# N32A032 register map
Vendor: Nationstech Ltd.; File version: 1.0
Registers are 32-bit, read-write, reset 0x0 unless marked. A register's access mark holds for its fields unless they carry their own. Offsets are from the block's base; [hi:lo] are bit positions; {n}, {i} and the like mark numbered series; 'fields as' and 'values as' point back to an identical list.

## BEEPER1 — Beeper unit
Base 0x40000000
Same registers: BEEPER2 0x40001400
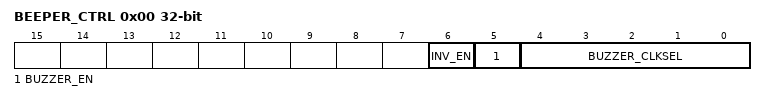
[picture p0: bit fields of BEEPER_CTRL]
0x00 BEEPER_CTRL
  [6] INV_EN, [5] BUZZER_EN, [4:0] BUZZER_CLKSEL

## CAN — Controller area network
Base 0x40006400
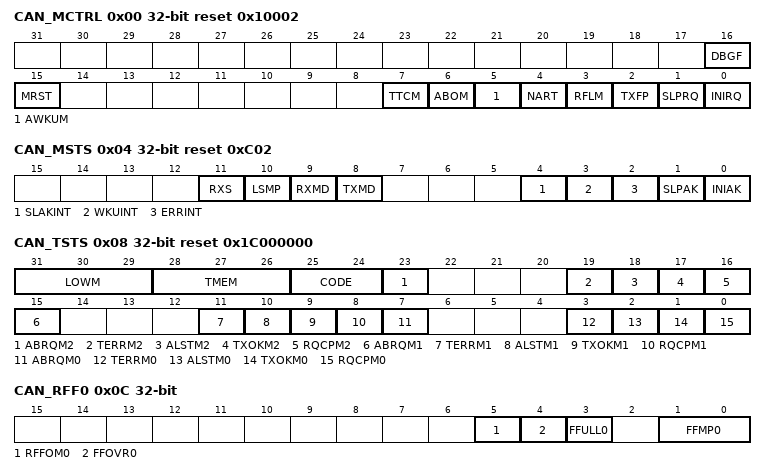
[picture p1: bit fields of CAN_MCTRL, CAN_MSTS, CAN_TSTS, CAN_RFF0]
0x00 CAN_MCTRL reset 0x10002
  [16] DBGF, [15] MRST, [7] TTCM, [6] ABOM, [5] AWKUM, [4] NART, [3] RFLM, [2] TXFP, [1] SLPRQ, [0] INIRQ
0x04 CAN_MSTS reset 0xC02
  [11] RXS, [10] LSMP, [9] RXMD, [8] TXMD, [4] SLAKINT, [3] WKUINT, [2] ERRINT, [1] SLPAK, [0] INIAK
0x08 CAN_TSTS reset 0x1C000000
  [31:29] LOWM, [28:26] TMEM, [25:24] CODE, [23] ABRQM2, [19] TERRM2, [18] ALSTM2, [17] TXOKM2, [16] RQCPM2, [15] ABRQM1, [11] TERRM1, [10] ALSTM1, [9] TXOKM1, [8] RQCPM1, [7] ABRQM0, [3] TERRM0, [2] ALSTM0, [1] TXOKM0, [0] RQCPM0
0x0C CAN_RFF0
  [5] RFFOM0, [4] FFOVR0, [3] FFULL0, [1:0] FFMP0
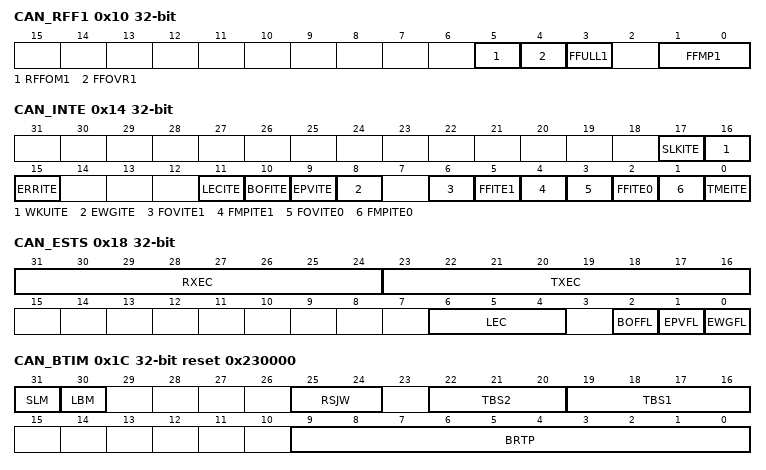
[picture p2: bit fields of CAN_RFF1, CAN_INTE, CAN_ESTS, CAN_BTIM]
0x10 CAN_RFF1
  [5] RFFOM1, [4] FFOVR1, [3] FFULL1, [1:0] FFMP1
0x14 CAN_INTE
  [17] SLKITE, [16] WKUITE, [15] ERRITE, [11] LECITE, [10] BOFITE, [9] EPVITE, [8] EWGITE, [6] FOVITE1, [5] FFITE1, [4] FMPITE1, [3] FOVITE0, [2] FFITE0, [1] FMPITE0, [0] TMEITE
0x18 CAN_ESTS
  [31:24] RXEC, [23:16] TXEC, [6:4] LEC, [2] BOFFL, [1] EPVFL, [0] EWGFL
0x1C CAN_BTIM reset 0x230000
  [31] SLM, [30] LBM, [25:24] RSJW, [22:20] TBS2, [19:16] TBS1, [9:0] BRTP
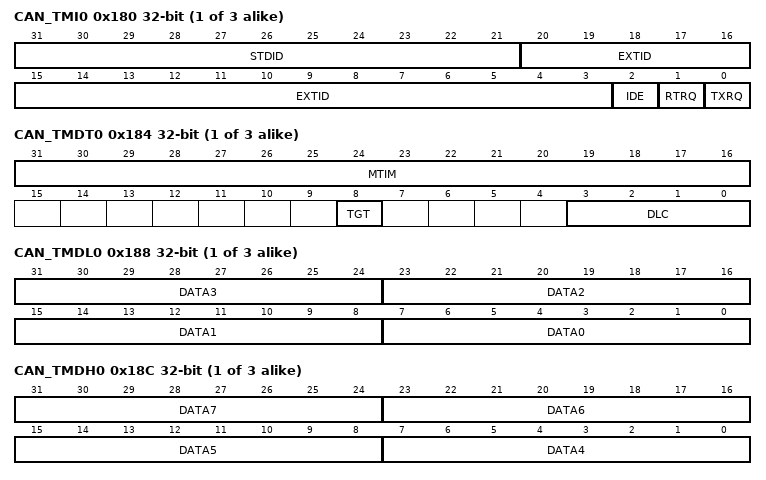
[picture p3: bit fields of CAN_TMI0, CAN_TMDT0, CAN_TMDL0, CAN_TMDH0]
{0x180+0x10*i} CAN_TMI{i} (i=0..2)
  [31:21] STDID, [20:3] EXTID, [2] IDE, [1] RTRQ, [0] TXRQ
{0x184+0x10*i} CAN_TMDT{i} (i=0..2)
  [31:16] MTIM, [8] TGT, [3:0] DLC
{0x188+0x10*i} CAN_TMDL{i} (i=0..2)
  [8n+7:8n] DATA{n} (n=0..3)
{0x18C+0x10*i} CAN_TMDH{i} (i=0..2)
  [8n-25:8n-32] DATA{n} (n=4..7)
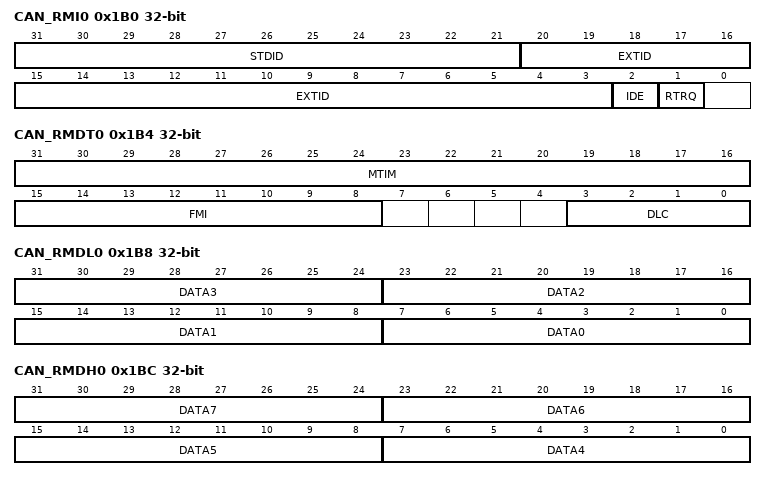
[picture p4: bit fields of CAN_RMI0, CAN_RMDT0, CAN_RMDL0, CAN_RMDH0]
0x1B0 CAN_RMI0
  [31:21] STDID, [20:3] EXTID, [2] IDE, [1] RTRQ
0x1B4 CAN_RMDT0
  [31:16] MTIM, [15:8] FMI, [3:0] DLC
0x1B8 CAN_RMDL0
  [8n+7:8n] DATA{n} (n=0..3)
0x1BC CAN_RMDH0
  [8n-25:8n-32] DATA{n} (n=4..7)
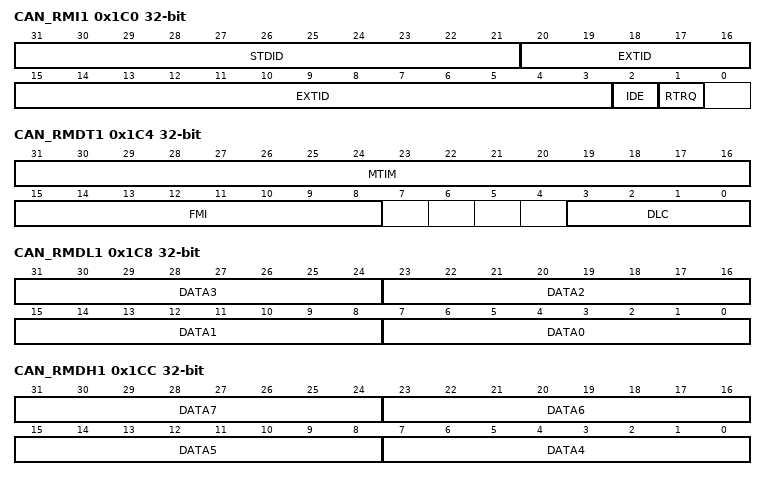
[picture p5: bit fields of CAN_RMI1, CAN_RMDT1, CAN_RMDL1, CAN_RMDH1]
0x1C0 CAN_RMI1
  [31:21] STDID, [20:3] EXTID, [2] IDE, [1] RTRQ
0x1C4 CAN_RMDT1
  [31:16] MTIM, [15:8] FMI, [3:0] DLC
0x1C8 CAN_RMDL1
  [8n+7:8n] DATA{n} (n=0..3)
0x1CC CAN_RMDH1
  [8n-25:8n-32] DATA{n} (n=4..7)
0x200 CAN_FMC reset 0x1
  [0] FINITM
0x204 CAN_FM1
  [13:0] FB
0x20C CAN_FS1
  [13:0] FSC
0x214 CAN_FFA1
  [13:0] FAF
0x21C CAN_FA1
  [13:0] FAC
{0x240+8i} CAN_F{i}B1 (i=0..13)
  [31:0] FBC
{0x244+8i} CAN_F{i}B2 (i=0..13)
  [31:0] FBC

## COMP — comparator
Base 0x40002400
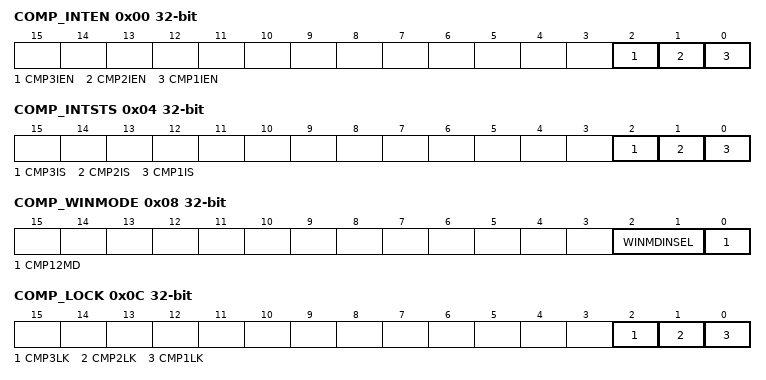
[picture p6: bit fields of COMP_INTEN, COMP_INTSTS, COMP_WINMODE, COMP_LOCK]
0x00 COMP_INTEN
  [2] CMP3IEN, [1] CMP2IEN, [0] CMP1IEN
0x04 COMP_INTSTS
  [2] CMP3IS, [1] CMP2IS, [0] CMP1IS
0x08 COMP_WINMODE
  [2:1] WINMDINSEL, [0] CMP12MD
0x0C COMP_LOCK
  [2] CMP3LK, [1] CMP2LK, [0] CMP1LK
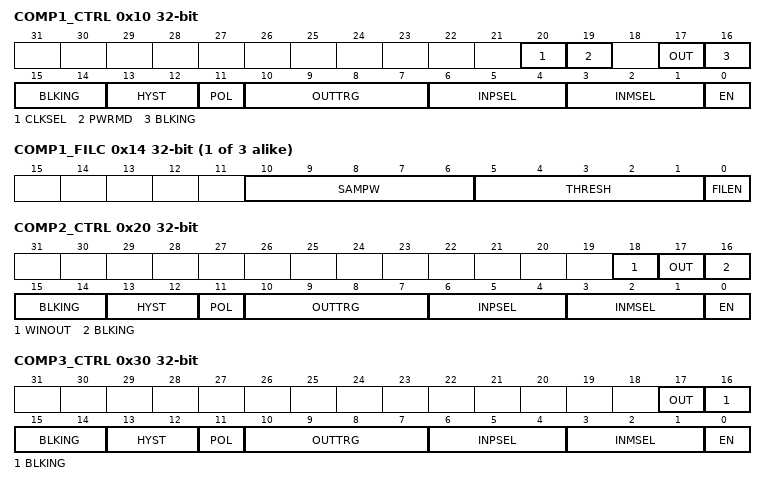
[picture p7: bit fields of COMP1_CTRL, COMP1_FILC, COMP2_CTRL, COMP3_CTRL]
0x10 COMP1_CTRL
  [20] CLKSEL
  [19] PWRMD
  [17] OUT
  [16:14] BLKING
  [13:12] HYST
  [11] POL
  [10:7] OUTTRG — OUTSEL
  [6:4] INPSEL
  [3:1] INMSEL
  [0] EN
{0x4+0x10*i} COMP{i}_FILC (i=1..3)
  [10:6] SAMPW, [5:1] THRESH, [0] FILEN
{0x8+0x10*i} COMP{i}_FILP (i=1..3)
  [15:0] CLKPSC
0x20 COMP2_CTRL
  [18] WINOUT
  [17] OUT
  [16:14] BLKING
  [13:12] HYST
  [11] POL
  [10:7] OUTTRG — OUTSEL
  [6:4] INPSEL
  [3:1] INMSEL
  [0] EN
0x30 COMP3_CTRL
  [17] OUT
  [16:14] BLKING
  [13:12] HYST
  [11] POL
  [10:7] OUTTRG — OUTSEL
  [6:4] INPSEL
  [3:1] INMSEL
  [0] EN
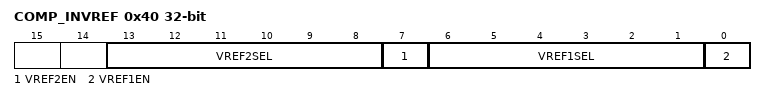
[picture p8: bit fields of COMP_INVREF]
0x40 COMP_INVREF (reset mask 0xFFF)
  [13:8] VREF2SEL, [7] VREF2EN, [6:1] VREF1SEL, [0] VREF1EN

## CRC — cyclic redundancy check
Base 0x40023000
0x00 CRC32DAT reset 0xFFFFFFFF
0x04 CRC32IDAT
  [7:0] CRC32IDAT
0x08 CRC32CTRL
  [0] RESET
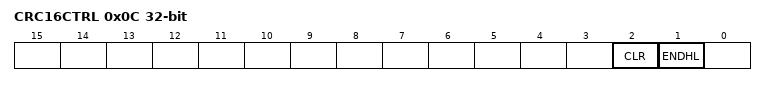
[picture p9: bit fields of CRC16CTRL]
0x0C CRC16CTRL
  [2] CLR, [1] ENDHL
0x10 CRC16DAT
  [7:0] CRC16DAT
0x14 CRC16D
  [15:0] CRC16D
0x18 LRC
  [7:0] LRCDAT

## DMA — Direct memory access controller
Base 0x40020000
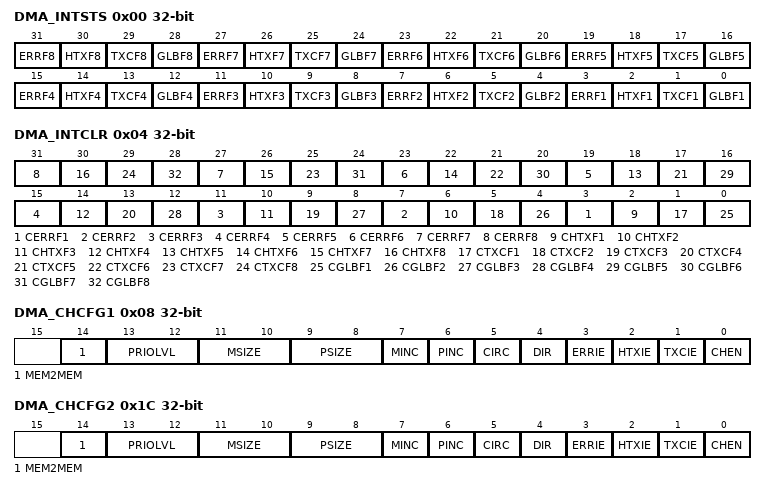
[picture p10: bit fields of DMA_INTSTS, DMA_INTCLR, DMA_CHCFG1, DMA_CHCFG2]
0x00 DMA_INTSTS
  [4n-1] ERRF{n} (n=1..8), [4n-2] HTXF{n} (n=1..8), [4n-3] TXCF{n} (n=1..8), [4n-4] GLBF{n} (n=1..8)
0x04 DMA_INTCLR
  [4n-1] CERRF{n} (n=1..8), [4n-2] CHTXF{n} (n=1..8), [4n-3] CTXCF{n} (n=1..8), [4n-4] CGLBF{n} (n=1..8)
0x08 DMA_CHCFG1
  [14] MEM2MEM, [13:12] PRIOLVL, [11:10] MSIZE, [9:8] PSIZE, [7] MINC, [6] PINC, [5] CIRC, [4] DIR, [3] ERRIE, [2] HTXIE, [1] TXCIE, [0] CHEN
0x0C DMA_TXNUM1
  [15:0] NDTX
0x10 DMA_PADDR1
  [31:0] ADDR
{0x0+0x14*i} DMA_MADDR{i} (i=1..8)
  [31:0] ADDR
{0x4+0x14*i} DMA_CHSEL{i} (i=1..8)
  [5:0] CH_SEL
0x1C DMA_CHCFG2
  fields as DMA_CHCFG1
0x20 DMA_TXNUM2
  [15:0] NDTX
0x24 DMA_PADDR2
  [31:0] ADDR
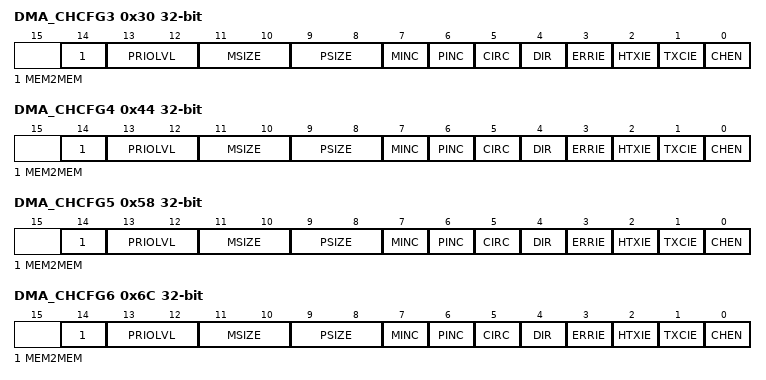
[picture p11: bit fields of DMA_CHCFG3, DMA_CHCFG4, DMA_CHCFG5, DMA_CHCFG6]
0x30 DMA_CHCFG3
  fields as DMA_CHCFG1
0x34 DMA_TXNUM3
  [15:0] NDTX
0x38 DMA_PADDR3
  [31:0] ADDR
0x44 DMA_CHCFG4
  fields as DMA_CHCFG1
0x48 DMA_TXNUM4
  [15:0] NDTX
0x4C DMA_PADDR4
  [31:0] ADDR
0x58 DMA_CHCFG5
  fields as DMA_CHCFG1
0x5C DMA_TXNUM5
  [15:0] NDTX
0x60 DMA_PADDR5
  [31:0] ADDR
0x6C DMA_CHCFG6
  fields as DMA_CHCFG1
0x70 DMA_TXNUM6
  [15:0] NDTX
0x74 DMA_PADDR6
  [31:0] ADDR
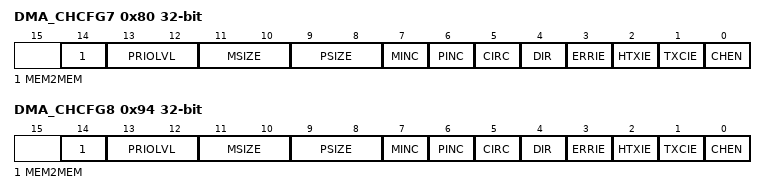
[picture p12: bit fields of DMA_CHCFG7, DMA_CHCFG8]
0x80 DMA_CHCFG7
  fields as DMA_CHCFG1
0x84 DMA_TXNUM7
  [15:0] NDTX
0x88 DMA_PADDR7
  [31:0] ADDR
0x94 DMA_CHCFG8
  fields as DMA_CHCFG1
0x98 DMA_TXNUM8
  [15:0] NDTX
0x9C DMA_PADDR8
  [31:0] ADDR
